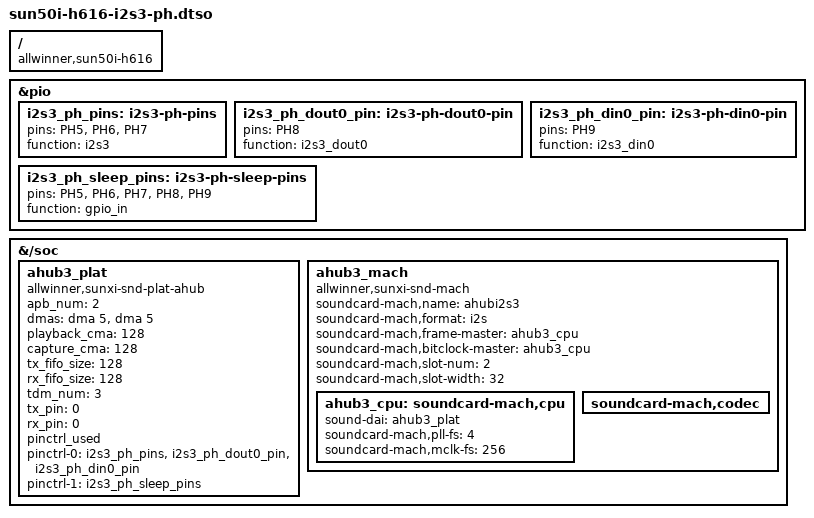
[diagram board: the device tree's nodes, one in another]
/dts-v1/;
/plugin/;

/*
 * I2S3 (audio hub interface 3) on PH5-PH9, as a 2-channel I2S master
 * card "ahubi2s3" with a dummy codec, using the Allwinner AHUB driver
 * (CONFIG_SND_SOC_SUNXI_AHUB). Same setup as the vendor BSP.
 *
 * Orange Pi Zero2, 26-pin header:
 *   pin 3  PH5  I2S3_MCLK (256 fs)
 *   pin 23 PH6  I2S3_BCLK
 *   pin 19 PH7  I2S3_LRCK
 *   pin 21 PH8  I2S3_DOUT0
 *   pin 24 PH9  I2S3_DIN0
 * Conflicts: spidev1_* / SPI1 (PH6-PH9), uart2-ph and uart2-ph-rts-cts
 * (PH5-PH8), i2c3-ph (PH5), i2c4-ph (PH6/PH7).
 */

/ {
	compatible = "allwinner,sun50i-h616", "allwinner,sun50i-h618";

	fragment@0 {
		target = <&pio>;
		__overlay__ {
			i2s3_ph_pins: i2s3-ph-pins {
				pins = "PH5", "PH6", "PH7";
				function = "i2s3";
			};

			i2s3_ph_dout0_pin: i2s3-ph-dout0-pin {
				pins = "PH8";
				function = "i2s3_dout0";
			};

			i2s3_ph_din0_pin: i2s3-ph-din0-pin {
				pins = "PH9";
				function = "i2s3_din0";
			};

			i2s3_ph_sleep_pins: i2s3-ph-sleep-pins {
				pins = "PH5", "PH6", "PH7", "PH8", "PH9";
				function = "gpio_in";
			};
		};
	};

	fragment@1 {
		target-path = "/soc";
		__overlay__ {
			ahub3_plat: ahub3_plat {
				#sound-dai-cells = <0>;
				compatible = "allwinner,sunxi-snd-plat-ahub";
				apb_num = <2>;		/* APBIF2, DMA DRQ 5 */
				dmas = <&dma 5>, <&dma 5>;
				dma-names = "tx", "rx";
				playback_cma = <128>;
				capture_cma = <128>;
				tx_fifo_size = <128>;
				rx_fifo_size = <128>;
				tdm_num = <3>;		/* I2S3 */
				tx_pin = <0>;		/* DOUT0 */
				rx_pin = <0>;		/* DIN0 */
				pinctrl_used;
				pinctrl-names = "default", "sleep";
				pinctrl-0 = <&i2s3_ph_pins>, <&i2s3_ph_dout0_pin>,
					    <&i2s3_ph_din0_pin>;
				pinctrl-1 = <&i2s3_ph_sleep_pins>;
				status = "okay";
			};

			ahub3_mach: ahub3_mach {
				compatible = "allwinner,sunxi-snd-mach";
				soundcard-mach,name = "ahubi2s3";
				soundcard-mach,format = "i2s";
				soundcard-mach,frame-master = <&ahub3_cpu>;
				soundcard-mach,bitclock-master = <&ahub3_cpu>;
				soundcard-mach,slot-num = <2>;
				soundcard-mach,slot-width = <32>;
				status = "okay";

				ahub3_cpu: soundcard-mach,cpu {
					sound-dai = <&ahub3_plat>;
					soundcard-mach,pll-fs = <4>;
					soundcard-mach,mclk-fs = <256>;
				};

				soundcard-mach,codec {
				};
			};
		};
	};
};
